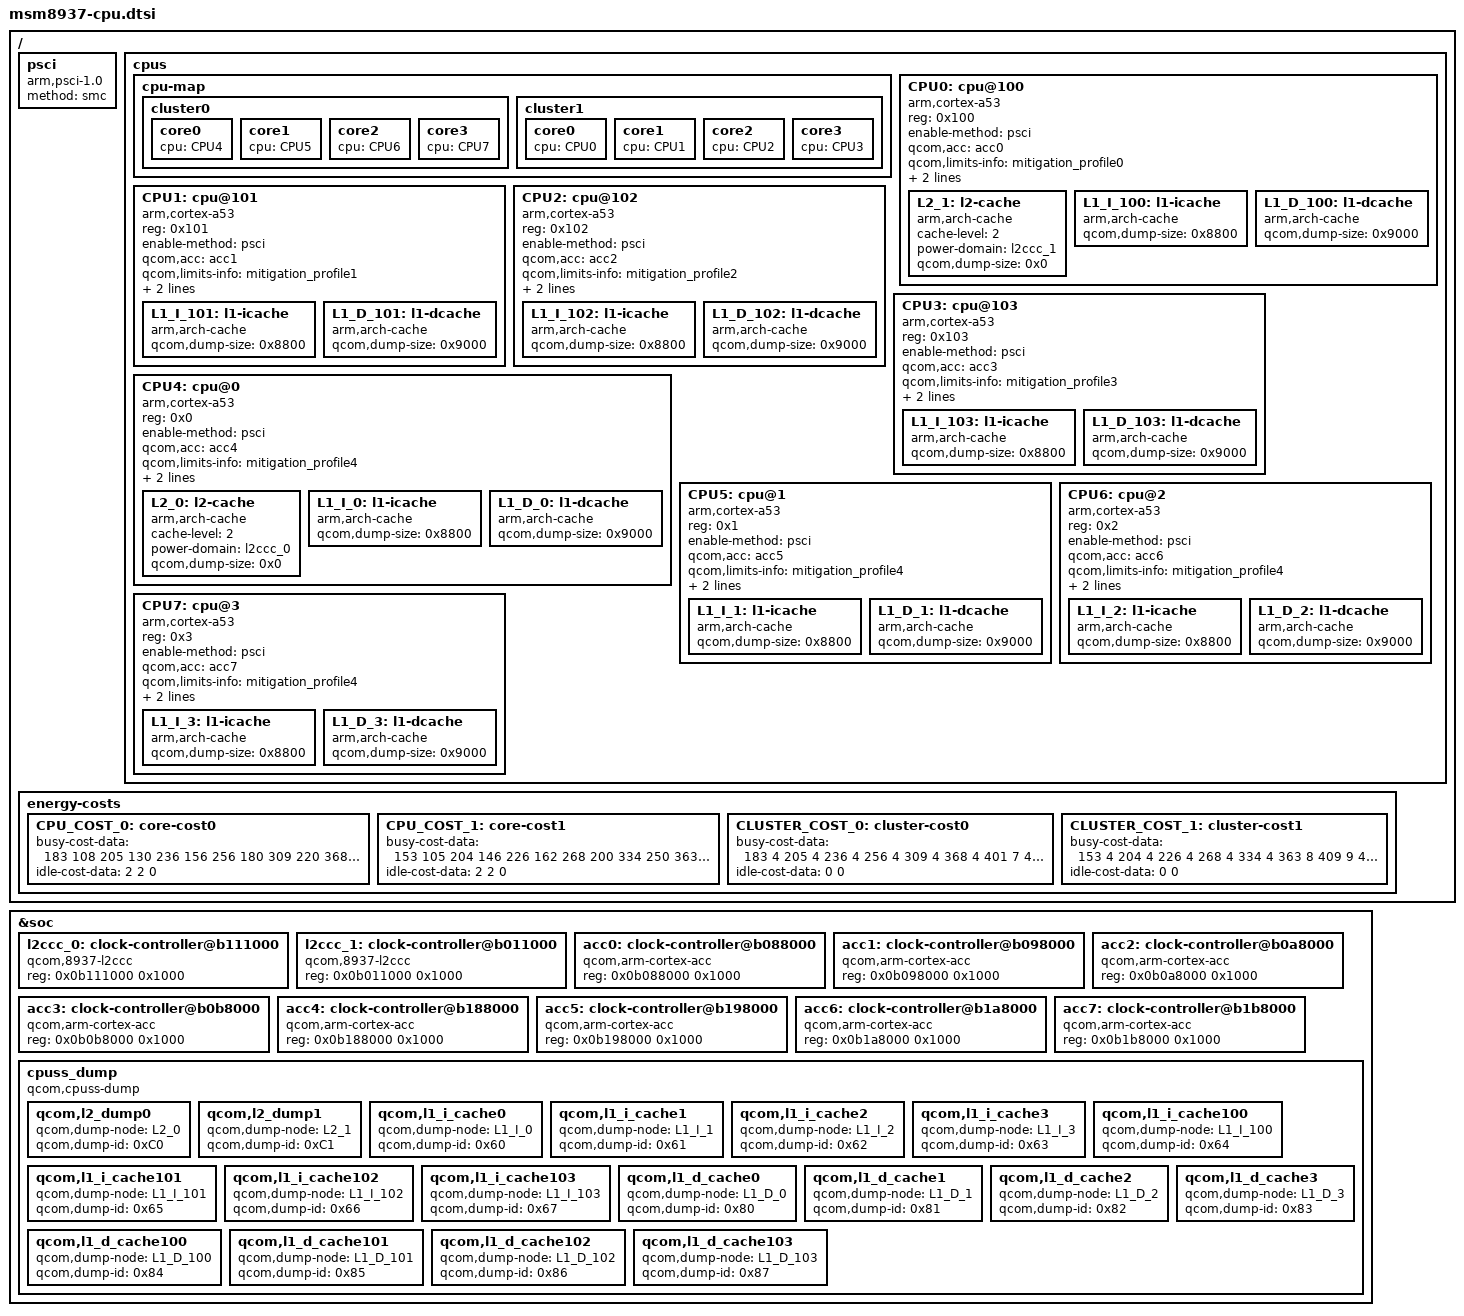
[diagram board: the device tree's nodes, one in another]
/*
 * Copyright (c) 2015-2016, The Linux Foundation. All rights reserved.
 *
 * This program is free software; you can redistribute it and/or modify
 * it under the terms of the GNU General Public License version 2 and
 * only version 2 as published by the Free Software Foundation.
 *
 * This program is distributed in the hope that it will be useful,
 * but WITHOUT ANY WARRANTY; without even the implied warranty of
 * MERCHANTABILITY or FITNESS FOR A PARTICULAR PURPOSE.  See the
 * GNU General Public License for more details.
 */

/ {
	psci {
		compatible = "arm,psci-1.0";
		method = "smc";
	};

	cpus {
		#address-cells = <1>;
		#size-cells = <0>;
		cpu-map {
			cluster0 {
				core0 {
					cpu = <&CPU4>;
				};
				core1 {
					cpu = <&CPU5>;
				};
				core2 {
					cpu = <&CPU6>;
				};
				core3 {
					cpu = <&CPU7>;
				};
			};

			cluster1 {
				core0 {
					cpu = <&CPU0>;
				};
				core1 {
					cpu = <&CPU1>;
				};
				core2 {
					cpu = <&CPU2>;
				};
				core3 {
					cpu = <&CPU3>;
				};
			};
		};

		CPU0: cpu@100 {
			device_type = "cpu";
			compatible = "arm,cortex-a53";
			reg = <0x100>;
			enable-method = "psci";
			qcom,acc = <&acc0>;
			qcom,limits-info = <&mitigation_profile0>;
			next-level-cache = <&L2_1>;
			sched-energy-costs = <&CPU_COST_0 &CLUSTER_COST_0>;
			L2_1: l2-cache {
			      compatible = "arm,arch-cache";
			      cache-level = <2>;
			      power-domain = <&l2ccc_1>;
			      /* A53 L2 dump not supported */
			      qcom,dump-size = <0x0>;
			};
			L1_I_100: l1-icache {
				compatible = "arm,arch-cache";
				qcom,dump-size = <0x8800>;
			};
			L1_D_100: l1-dcache {
				compatible = "arm,arch-cache";
				qcom,dump-size = <0x9000>;
			};
		};

		CPU1: cpu@101 {
			device_type = "cpu";
			compatible = "arm,cortex-a53";
			reg = <0x101>;
			enable-method = "psci";
			qcom,acc = <&acc1>;
			qcom,limits-info = <&mitigation_profile1>;
			next-level-cache = <&L2_1>;
			sched-energy-costs = <&CPU_COST_0 &CLUSTER_COST_0>;
			L1_I_101: l1-icache {
				compatible = "arm,arch-cache";
				qcom,dump-size = <0x8800>;
			};
			L1_D_101: l1-dcache {
				compatible = "arm,arch-cache";
				qcom,dump-size = <0x9000>;
			};
		};

		CPU2: cpu@102 {
			device_type = "cpu";
			compatible = "arm,cortex-a53";
			reg = <0x102>;
			enable-method = "psci";
			qcom,acc = <&acc2>;
			qcom,limits-info = <&mitigation_profile2>;
			next-level-cache = <&L2_1>;
			sched-energy-costs = <&CPU_COST_0 &CLUSTER_COST_0>;
			L1_I_102: l1-icache {
				compatible = "arm,arch-cache";
				qcom,dump-size = <0x8800>;
			};
			L1_D_102: l1-dcache {
				compatible = "arm,arch-cache";
				qcom,dump-size = <0x9000>;
			};
		};

		CPU3: cpu@103 {
			device_type = "cpu";
			compatible = "arm,cortex-a53";
			reg = <0x103>;
			enable-method = "psci";
			qcom,acc = <&acc3>;
			qcom,limits-info = <&mitigation_profile3>;
			next-level-cache = <&L2_1>;
			sched-energy-costs = <&CPU_COST_0 &CLUSTER_COST_0>;
			L1_I_103: l1-icache {
				compatible = "arm,arch-cache";
				qcom,dump-size = <0x8800>;
			};
			L1_D_103: l1-dcache {
				compatible = "arm,arch-cache";
				qcom,dump-size = <0x9000>;
			};
		};

		CPU4: cpu@0 {
			device_type = "cpu";
			compatible = "arm,cortex-a53";
			reg = <0x0>;
			enable-method = "psci";
			qcom,acc = <&acc4>;
			qcom,limits-info = <&mitigation_profile4>;
			next-level-cache = <&L2_0>;
			sched-energy-costs = <&CPU_COST_1 &CLUSTER_COST_1>;
			L2_0: l2-cache {
			      compatible = "arm,arch-cache";
			      cache-level = <2>;
			      power-domain = <&l2ccc_0>;
			      qcom,dump-size = <0x0>;
			};
			L1_I_0: l1-icache {
				compatible = "arm,arch-cache";
				qcom,dump-size = <0x8800>;
			};
			L1_D_0: l1-dcache {
				compatible = "arm,arch-cache";
				qcom,dump-size = <0x9000>;
			};
		};

		CPU5: cpu@1 {
			device_type = "cpu";
			compatible = "arm,cortex-a53";
			reg = <0x1>;
			enable-method = "psci";
			qcom,acc = <&acc5>;
			qcom,limits-info = <&mitigation_profile4>;
			next-level-cache = <&L2_0>;
			sched-energy-costs = <&CPU_COST_1 &CLUSTER_COST_1>;
			L1_I_1: l1-icache {
				compatible = "arm,arch-cache";
				qcom,dump-size = <0x8800>;
			};
			L1_D_1: l1-dcache {
				compatible = "arm,arch-cache";
				qcom,dump-size = <0x9000>;
			};
		};

		CPU6: cpu@2 {
			device_type = "cpu";
			compatible = "arm,cortex-a53";
			reg = <0x2>;
			enable-method = "psci";
			qcom,acc = <&acc6>;
			qcom,limits-info = <&mitigation_profile4>;
			next-level-cache = <&L2_0>;
			sched-energy-costs = <&CPU_COST_1 &CLUSTER_COST_1>;
			L1_I_2: l1-icache {
				compatible = "arm,arch-cache";
				qcom,dump-size = <0x8800>;
			};
			L1_D_2: l1-dcache {
				compatible = "arm,arch-cache";
				qcom,dump-size = <0x9000>;
			};
		};

		CPU7: cpu@3 {
			device_type = "cpu";
			compatible = "arm,cortex-a53";
			reg = <0x3>;
			enable-method = "psci";
			qcom,acc = <&acc7>;
			qcom,limits-info = <&mitigation_profile4>;
			next-level-cache = <&L2_0>;
			sched-energy-costs = <&CPU_COST_1 &CLUSTER_COST_1>;
			L1_I_3: l1-icache {
				compatible = "arm,arch-cache";
				qcom,dump-size = <0x8800>;
			};
			L1_D_3: l1-dcache {
				compatible = "arm,arch-cache";
				qcom,dump-size = <0x9000>;
			};
		};
	};

	energy-costs {
		CPU_COST_0: core-cost0 {
			busy-cost-data = <
					183 108
					205 130
					236 156
					256 180
					309 220
					368 260
					401 300
					441 340
					459 370
					508 440
					531 490
					584 555
					613 610
					643 680
					682 775
					713 860
					737 950
					792 1110
					837 1350
					856 1400
					902 1700
					932 1900
					963 2100
					993 2300
					1024 2500
			>;
			idle-cost-data = <
				      2 2 0
			>;
		};
		CPU_COST_1: core-cost1 {
			busy-cost-data = <
					153 105
					204 146
					226 162
					268 200
					334 250
					363 300
					409 350
					457 450
					494 475
					537 600
					551 620
					596 700
					636 835
					691 1035
					723 1140
					772 1260
			>;
			idle-cost-data = <
				      2 2 0
			>;
		};
		CLUSTER_COST_0: cluster-cost0 {
			busy-cost-data = <
					183 4
					205 4
					236 4
					256 4
					309 4
					368 4
					401 7
					441 10
					459 15
					508 16
					531 21
					584 22
					613 29
					643 32
					682 42
					713 49
					737 41
					792 52
					837 62
					856 69
					902 75
					932 81
					963 90
					993 93
					1024 96
			>;
			idle-cost-data = <
					0
					0
			>;
		};
		CLUSTER_COST_1: cluster-cost1 {
			busy-cost-data = <
					153 4
					204 4
					226 4
					268 4
					334 4
					363 8
					409 9
					457 16
					494 21
					537 22
					551 29
					596 32
					636 42
					691 49
					723 41
					772 52
			>;
			idle-cost-data = <
					0
					0
			>;
		};
	};
};

&soc {
	l2ccc_0: clock-controller@b111000 {
		compatible = "qcom,8937-l2ccc";
		reg = <0x0b111000 0x1000>;
	};

	l2ccc_1: clock-controller@b011000 {
		compatible = "qcom,8937-l2ccc";
		reg = <0x0b011000 0x1000>;
	};

	acc0:clock-controller@b088000 {
		compatible = "qcom,arm-cortex-acc";
		reg = <0x0b088000 0x1000>;
	};

	acc1:clock-controller@b098000 {
		compatible = "qcom,arm-cortex-acc";
		reg = <0x0b098000 0x1000>;
	};

	acc2:clock-controller@b0a8000 {
		compatible = "qcom,arm-cortex-acc";
		reg = <0x0b0a8000 0x1000>;
	};

	acc3:clock-controller@b0b8000 {
		compatible = "qcom,arm-cortex-acc";
		reg = <0x0b0b8000 0x1000>;
	};

	acc4:clock-controller@b188000 {
		compatible = "qcom,arm-cortex-acc";
		reg = <0x0b188000 0x1000>;
	};

	acc5:clock-controller@b198000 {
		compatible = "qcom,arm-cortex-acc";
		reg = <0x0b198000 0x1000>;
	};

	acc6:clock-controller@b1a8000 {
		compatible = "qcom,arm-cortex-acc";
		reg = <0x0b1a8000 0x1000>;
	};

	acc7:clock-controller@b1b8000 {
		compatible = "qcom,arm-cortex-acc";
		reg = <0x0b1b8000 0x1000>;
	};

	cpuss_dump {
		compatible = "qcom,cpuss-dump";
		qcom,l2_dump0 {
			/* L2 cache dump for A53 cluster */
			qcom,dump-node = <&L2_0>;
			qcom,dump-id = <0xC0>;
		};
		qcom,l2_dump1 {
			/* L2 cache dump for A53 cluster */
			qcom,dump-node = <&L2_1>;
			qcom,dump-id = <0xC1>;
		};
		qcom,l1_i_cache0 {
			qcom,dump-node = <&L1_I_0>;
			qcom,dump-id = <0x60>;
		};
		qcom,l1_i_cache1 {
			qcom,dump-node = <&L1_I_1>;
			qcom,dump-id = <0x61>;
		};
		qcom,l1_i_cache2 {
			qcom,dump-node = <&L1_I_2>;
			qcom,dump-id = <0x62>;
		};
		qcom,l1_i_cache3 {
			qcom,dump-node = <&L1_I_3>;
			qcom,dump-id = <0x63>;
		};
		qcom,l1_i_cache100 {
			qcom,dump-node = <&L1_I_100>;
			qcom,dump-id = <0x64>;
		};
		qcom,l1_i_cache101 {
			qcom,dump-node = <&L1_I_101>;
			qcom,dump-id = <0x65>;
		};
		qcom,l1_i_cache102 {
			qcom,dump-node = <&L1_I_102>;
			qcom,dump-id = <0x66>;
		};
		qcom,l1_i_cache103 {
			qcom,dump-node = <&L1_I_103>;
			qcom,dump-id = <0x67>;
		};
		qcom,l1_d_cache0 {
			qcom,dump-node = <&L1_D_0>;
			qcom,dump-id = <0x80>;
		};
		qcom,l1_d_cache1 {
			qcom,dump-node = <&L1_D_1>;
			qcom,dump-id = <0x81>;
		};
		qcom,l1_d_cache2 {
			qcom,dump-node = <&L1_D_2>;
			qcom,dump-id = <0x82>;
		};
		qcom,l1_d_cache3 {
			qcom,dump-node = <&L1_D_3>;
			qcom,dump-id = <0x83>;
		};
		qcom,l1_d_cache100 {
			qcom,dump-node = <&L1_D_100>;
			qcom,dump-id = <0x84>;
		};
		qcom,l1_d_cache101 {
			qcom,dump-node = <&L1_D_101>;
			qcom,dump-id = <0x85>;
		};
		qcom,l1_d_cache102 {
			qcom,dump-node = <&L1_D_102>;
			qcom,dump-id = <0x86>;
		};
		qcom,l1_d_cache103 {
			qcom,dump-node = <&L1_D_103>;
			qcom,dump-id = <0x87>;
		};
	};
};
